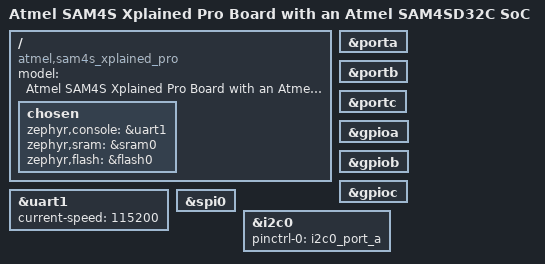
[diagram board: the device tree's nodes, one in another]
/*
 * Copyright (c) Justin Watson 2017
 * SPDX-License-Identifier: Apache-2.0
 */

/dts-v1/;

#include <atmel/sam4s.dtsi>

/ {
	model = "Atmel SAM4S Xplained Pro Board with an Atmel SAM4SD32C SoC";
	compatible = "atmel,sam4s_xplained_pro", "atmel,atsam4sd32c", "atmel,sam4s";

	chosen {
		zephyr,console = &uart1;
		zephyr,sram = &sram0;
		zephyr,flash = &flash0;
	};
};

&uart1 {
	current-speed = <115200>;
	status = "ok";
};

&porta {
	status = "ok";
};

&portb {
	status = "ok";
};

&portc {
	status = "ok";
};

&gpioa {
	status = "ok";
};

&gpiob {
	status = "ok";
};

&gpioc {
	status = "ok";
};

&spi0 {
	status = "ok";
};

&i2c0 {
	pinctrl-0 = <&i2c0_port_a>;
	pinctrl-names = "default";
	status = "ok";
};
